AUTOSAR XML (schema 00044)
package /E40_Platform_System_SystemPackage/Components
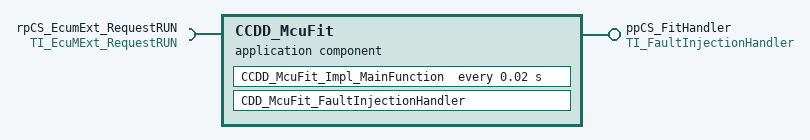
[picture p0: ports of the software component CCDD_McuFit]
  application sw component type CCDD_McuFit
    provide port ppCS_FitHandler: server-com-spec{operation=FaultInjectionHandler, queue-length=1}, provided-interface=TI_FaultInjectionHandler
    require port rpCS_EcumExt_RequestRUN: client-com-spec=RequestRUN, required-interface=TI_EcuMExt_RequestRUN
    behavior IB_CCDD_McuFit
      operation invoked event OIE_ppCS_FitHandler_CDD_McuFit_FaultInjectionHandlerTrigByFaultInjectionHandler: start-on-event=CDD_McuFit_FaultInjectionHandler, operation=ppCS_FitHandler.FaultInjectionHandler
      timing event TECCDD_McuFit_Impl_MainFunction: start-on-event=CCDD_McuFit_Impl_MainFunction, period=0.02
      port-api-options:
        enable-take-address=false, indirect-api=false, port=ppCS_FitHandler
        enable-take-address=false, indirect-api=false, port=rpCS_EcumExt_RequestRUN
      runnable CDD_McuFit_FaultInjectionHandler: can-be-invoked-concurrently=true
      runnable CCDD_McuFit_Impl_MainFunction: can-be-invoked-concurrently=true
        sync call OA_rpCS_EcumExt_RequestRUN_RequestRUN: operation=rpCS_EcumExt_RequestRUN.RequestRUN
  swc implementation IMPL_CCDD_McuFit: behavior=IB_CCDD_McuFit
